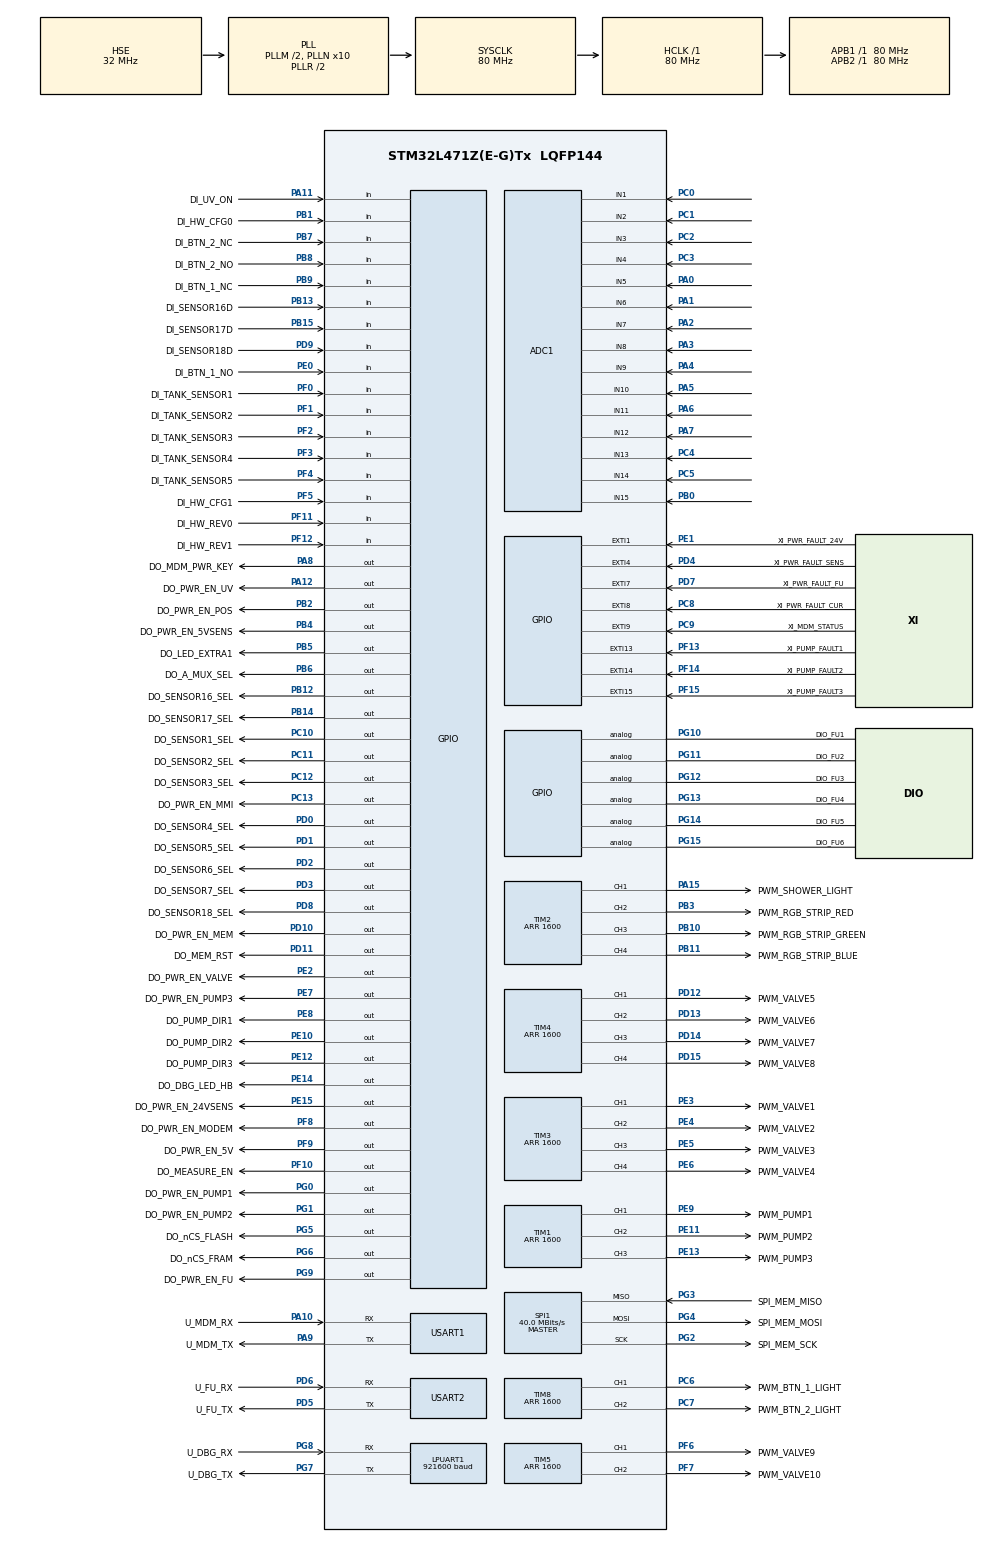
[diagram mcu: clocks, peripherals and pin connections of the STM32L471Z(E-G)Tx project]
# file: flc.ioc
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ADC1.Channel-0\#ChannelRegularConversion=ADC_CHANNEL_1
ADC1.Channel-1\#ChannelRegularConversion=ADC_CHANNEL_2
ADC1.Channel-10\#ChannelRegularConversion=ADC_CHANNEL_11
ADC1.Channel-11\#ChannelRegularConversion=ADC_CHANNEL_12
ADC1.Channel-12\#ChannelRegularConversion=ADC_CHANNEL_13
ADC1.Channel-13\#ChannelRegularConversion=ADC_CHANNEL_14
ADC1.Channel-14\#ChannelRegularConversion=ADC_CHANNEL_15
ADC1.Channel-2\#ChannelRegularConversion=ADC_CHANNEL_3
ADC1.Channel-3\#ChannelRegularConversion=ADC_CHANNEL_4
ADC1.Channel-4\#ChannelRegularConversion=ADC_CHANNEL_5
ADC1.Channel-5\#ChannelRegularConversion=ADC_CHANNEL_6
ADC1.Channel-6\#ChannelRegularConversion=ADC_CHANNEL_7
ADC1.Channel-7\#ChannelRegularConversion=ADC_CHANNEL_8
ADC1.Channel-8\#ChannelRegularConversion=ADC_CHANNEL_9
ADC1.Channel-9\#ChannelRegularConversion=ADC_CHANNEL_10
ADC1.ClockPrescaler=ADC_CLOCK_ASYNC_DIV12
ADC1.DMAContinuousRequests=ENABLE
ADC1.NbrOfConversion=15
ADC1.NbrOfConversionFlag=1
ADC1.OffsetNumber-0\#ChannelRegularConversion=ADC_OFFSET_NONE
ADC1.OffsetNumber-1\#ChannelRegularConversion=ADC_OFFSET_NONE
ADC1.OffsetNumber-10\#ChannelRegularConversion=ADC_OFFSET_NONE
ADC1.OffsetNumber-11\#ChannelRegularConversion=ADC_OFFSET_NONE
ADC1.OffsetNumber-12\#ChannelRegularConversion=ADC_OFFSET_NONE
ADC1.OffsetNumber-13\#ChannelRegularConversion=ADC_OFFSET_NONE
ADC1.OffsetNumber-14\#ChannelRegularConversion=ADC_OFFSET_NONE
ADC1.OffsetNumber-2\#ChannelRegularConversion=ADC_OFFSET_NONE
ADC1.OffsetNumber-3\#ChannelRegularConversion=ADC_OFFSET_NONE
ADC1.OffsetNumber-4\#ChannelRegularConversion=ADC_OFFSET_NONE
ADC1.OffsetNumber-5\#ChannelRegularConversion=ADC_OFFSET_NONE
ADC1.OffsetNumber-6\#ChannelRegularConversion=ADC_OFFSET_NONE
ADC1.OffsetNumber-7\#ChannelRegularConversion=ADC_OFFSET_NONE
ADC1.OffsetNumber-8\#ChannelRegularConversion=ADC_OFFSET_NONE
ADC1.OffsetNumber-9\#ChannelRegularConversion=ADC_OFFSET_NONE
ADC1.Overrun=ADC_OVR_DATA_OVERWRITTEN
ADC1.Rank-0\#ChannelRegularConversion=1
ADC1.Rank-1\#ChannelRegularConversion=2
ADC1.Rank-10\#ChannelRegularConversion=11
ADC1.Rank-11\#ChannelRegularConversion=12
ADC1.Rank-12\#ChannelRegularConversion=13
ADC1.Rank-13\#ChannelRegularConversion=14
ADC1.Rank-14\#ChannelRegularConversion=15
ADC1.Rank-2\#ChannelRegularConversion=3
ADC1.Rank-3\#ChannelRegularConversion=4
ADC1.Rank-4\#ChannelRegularConversion=5
ADC1.Rank-5\#ChannelRegularConversion=6
ADC1.Rank-6\#ChannelRegularConversion=7
ADC1.Rank-7\#ChannelRegularConversion=8
ADC1.Rank-8\#ChannelRegularConversion=9
ADC1.Rank-9\#ChannelRegularConversion=10
ADC1.SamplingTime-0\#ChannelRegularConversion=ADC_SAMPLETIME_2CYCLES_5
ADC1.SamplingTime-1\#ChannelRegularConversion=ADC_SAMPLETIME_2CYCLES_5
ADC1.SamplingTime-10\#ChannelRegularConversion=ADC_SAMPLETIME_2CYCLES_5
ADC1.SamplingTime-11\#ChannelRegularConversion=ADC_SAMPLETIME_2CYCLES_5
ADC1.SamplingTime-12\#ChannelRegularConversion=ADC_SAMPLETIME_2CYCLES_5
ADC1.SamplingTime-13\#ChannelRegularConversion=ADC_SAMPLETIME_2CYCLES_5
ADC1.SamplingTime-14\#ChannelRegularConversion=ADC_SAMPLETIME_2CYCLES_5
ADC1.SamplingTime-2\#ChannelRegularConversion=ADC_SAMPLETIME_2CYCLES_5
ADC1.SamplingTime-3\#ChannelRegularConversion=ADC_SAMPLETIME_2CYCLES_5
ADC1.SamplingTime-4\#ChannelRegularConversion=ADC_SAMPLETIME_2CYCLES_5
ADC1.SamplingTime-5\#ChannelRegularConversion=ADC_SAMPLETIME_2CYCLES_5
ADC1.SamplingTime-6\#ChannelRegularConversion=ADC_SAMPLETIME_2CYCLES_5
ADC1.SamplingTime-7\#ChannelRegularConversion=ADC_SAMPLETIME_2CYCLES_5
ADC1.SamplingTime-8\#ChannelRegularConversion=ADC_SAMPLETIME_2CYCLES_5
ADC1.SamplingTime-9\#ChannelRegularConversion=ADC_SAMPLETIME_2CYCLES_5
ADC1.master=1
Dma.ADC1.0.Direction=DMA_PERIPH_TO_MEMORY
Dma.ADC1.0.Instance=DMA1_Channel1
Dma.ADC1.0.MemDataAlignment=DMA_MDATAALIGN_WORD
Dma.ADC1.0.MemInc=DMA_MINC_ENABLE
Dma.ADC1.0.Mode=DMA_CIRCULAR
Dma.ADC1.0.PeriphDataAlignment=DMA_PDATAALIGN_HALFWORD
Dma.ADC1.0.PeriphInc=DMA_PINC_DISABLE
Dma.ADC1.0.Priority=DMA_PRIORITY_LOW
Dma.Request0=ADC1
IWDG.Prescaler=IWDG_PRESCALER_16
LPUART1.BaudRate=921600
LPUART1.WordLength=UART_WORDLENGTH_8B
Mcu.Family=STM32L4
Mcu.Name=STM32L471Z(E-G)Tx
Mcu.Package=LQFP144
NVIC.DMA1_Channel1_IRQn=true\:0\:0\:false\:false\:true\:false\:true
NVIC.EXTI15_10_IRQn=true\:0\:0\:false\:false\:true\:true\:true
NVIC.EXTI1_IRQn=true\:0\:0\:false\:false\:true\:true\:true
NVIC.EXTI4_IRQn=true\:0\:0\:false\:false\:true\:true\:true
NVIC.EXTI9_5_IRQn=true\:0\:0\:false\:false\:true\:true\:true
NVIC.LPUART1_IRQn=true\:0\:0\:false\:false\:true\:true\:true
NVIC.PriorityGroup=NVIC_PRIORITYGROUP_4
NVIC.SPI1_IRQn=true\:0\:0\:false\:false\:true\:true\:true
NVIC.TIM1_TRG_COM_TIM17_IRQn=true\:0\:0\:false\:false\:true\:false\:true
NVIC.TIM1_UP_TIM16_IRQn=true\:0\:0\:false\:false\:true\:false\:true
NVIC.TimeBase=TIM1_UP_TIM16_IRQn
NVIC.TimeBaseIP=TIM16
NVIC.USART1_IRQn=true\:0\:0\:false\:false\:true\:true\:true
NVIC.USART2_IRQn=true\:0\:0\:false\:false\:true\:true\:true
PA0.Signal=ADCx_IN5
PA1.Signal=ADCx_IN6
PA10.GPIO_Label=U_MDM_RX
PA10.GPIO_PuPd=GPIO_PULLUP
PA10.Mode=Asynchronous
PA10.Signal=USART1_RX
PA11.GPIO_Label=DI_UV_ON
PA11.GPIO_PuPd=GPIO_PULLDOWN
PA11.Signal=GPIO_Input
PA12.GPIO_Label=DO_PWR_EN_UV
PA12.PinState=GPIO_PIN_RESET
PA12.Signal=GPIO_Output
PA13\ (JTMS-SWDIO).GPIO_Label=SWDIO
PA13\ (JTMS-SWDIO).Mode=Serial_Wire
PA13\ (JTMS-SWDIO).Signal=SYS_JTMS-SWDIO
PA14\ (JTCK-SWCLK).GPIO_Label=SWCLK
PA14\ (JTCK-SWCLK).Mode=Serial_Wire
PA14\ (JTCK-SWCLK).Signal=SYS_JTCK-SWCLK
PA15\ (JTDI).GPIO_Label=PWM_SHOWER_LIGHT
PA15\ (JTDI).Signal=S_TIM2_CH1
PA2.Signal=ADCx_IN7
PA3.Signal=ADCx_IN8
PA4.Signal=ADCx_IN9
PA5.Signal=ADCx_IN10
PA6.Signal=ADCx_IN11
PA7.Signal=ADCx_IN12
PA8.GPIO_Label=DO_MDM_PWR_KEY
PA8.Signal=GPIO_Output
PA9.GPIO_Label=U_MDM_TX
PA9.GPIO_PuPd=GPIO_PULLUP
PA9.Mode=Asynchronous
PA9.Signal=USART1_TX
PB0.Signal=ADCx_IN15
PB1.GPIO_Label=DI_HW_CFG0
PB1.Signal=GPIO_Input
PB10.GPIO_Label=PWM_RGB_STRIP_GREEN
PB10.Signal=S_TIM2_CH3
PB11.GPIO_Label=PWM_RGB_STRIP_BLUE
PB11.Signal=S_TIM2_CH4
PB12.GPIO_Label=DO_SENSOR16_SEL
PB12.Signal=GPIO_Output
PB13.GPIO_Label=DI_SENSOR16D
PB13.GPIO_PuPd=GPIO_PULLUP
PB13.Signal=GPIO_Input
PB14.GPIO_Label=DO_SENSOR17_SEL
PB14.Signal=GPIO_Output
PB15.GPIO_Label=DI_SENSOR17D
PB15.GPIO_PuPd=GPIO_PULLUP
PB15.Signal=GPIO_Input
PB2.GPIO_Label=DO_PWR_EN_POS
PB2.PinState=GPIO_PIN_SET
PB2.Signal=GPIO_Output
PB3\ (JTDO-TRACESWO).GPIO_Label=PWM_RGB_STRIP_RED
PB3\ (JTDO-TRACESWO).Signal=S_TIM2_CH2
PB4\ (NJTRST).GPIO_Label=DO_PWR_EN_5VSENS
PB4\ (NJTRST).PinState=GPIO_PIN_SET
PB4\ (NJTRST).Signal=GPIO_Output
PB5.GPIO_Label=DO_LED_EXTRA1
PB5.Signal=GPIO_Output
PB6.GPIO_Label=DO_A_MUX_SEL
PB6.Signal=GPIO_Output
PB7.GPIO_Label=DI_BTN_2_NC
PB7.GPIO_PuPd=GPIO_PULLDOWN
PB7.Signal=GPIO_Input
PB8.GPIO_Label=DI_BTN_2_NO
PB8.GPIO_PuPd=GPIO_PULLDOWN
PB8.Signal=GPIO_Input
PB9.GPIO_Label=DI_BTN_1_NC
PB9.GPIO_PuPd=GPIO_PULLDOWN
PB9.Signal=GPIO_Input
PC0.Signal=ADCx_IN1
PC1.Signal=ADCx_IN2
PC10.GPIO_Label=DO_SENSOR1_SEL
PC10.Signal=GPIO_Output
PC11.GPIO_Label=DO_SENSOR2_SEL
PC11.Signal=GPIO_Output
PC12.GPIO_Label=DO_SENSOR3_SEL
PC12.Signal=GPIO_Output
PC13.GPIO_Label=DO_PWR_EN_MMI
PC13.PinState=GPIO_PIN_RESET
PC13.Signal=GPIO_Output
PC14-OSC32_IN\ (PC14).Mode=LSE-External-Oscillator
PC14-OSC32_IN\ (PC14).Signal=RCC_OSC32_IN
PC15-OSC32_OUT\ (PC15).Mode=LSE-External-Oscillator
PC15-OSC32_OUT\ (PC15).Signal=RCC_OSC32_OUT
PC2.Signal=ADCx_IN3
PC3.Signal=ADCx_IN4
PC4.Signal=ADCx_IN13
PC5.Signal=ADCx_IN14
PC6.GPIO_Label=PWM_BTN_1_LIGHT
PC6.Signal=S_TIM8_CH1
PC7.GPIO_Label=PWM_BTN_2_LIGHT
PC7.Signal=S_TIM8_CH2
PC8.GPIO_Label=XI_PWR_FAULT_CUR
PC8.GPIO_ModeDefaultEXTI=GPIO_MODE_IT_FALLING
PC8.GPIO_PuPd=GPIO_PULLUP
PC8.Signal=GPXTI8
PC9.GPIO_Label=XI_MDM_STATUS
PC9.GPIO_ModeDefaultEXTI=GPIO_MODE_IT_RISING_FALLING
PC9.GPIO_PuPd=GPIO_PULLDOWN
PC9.Signal=GPXTI9
PD0.GPIO_Label=DO_SENSOR4_SEL
PD0.Signal=GPIO_Output
PD1.GPIO_Label=DO_SENSOR5_SEL
PD1.Signal=GPIO_Output
PD10.GPIO_Label=DO_PWR_EN_MEM
PD10.PinState=GPIO_PIN_RESET
PD10.Signal=GPIO_Output
PD11.GPIO_Label=DO_MEM_RST
PD11.PinState=GPIO_PIN_SET
PD11.Signal=GPIO_Output
PD12.GPIO_Label=PWM_VALVE5
PD12.GPIO_Speed=GPIO_SPEED_FREQ_VERY_HIGH
PD12.Signal=S_TIM4_CH1
PD13.GPIO_Label=PWM_VALVE6
PD13.GPIO_Speed=GPIO_SPEED_FREQ_VERY_HIGH
PD13.Signal=S_TIM4_CH2
PD14.GPIO_Label=PWM_VALVE7
PD14.GPIO_Speed=GPIO_SPEED_FREQ_VERY_HIGH
PD14.Signal=S_TIM4_CH3
PD15.GPIO_Label=PWM_VALVE8
PD15.GPIO_Speed=GPIO_SPEED_FREQ_VERY_HIGH
PD15.Signal=S_TIM4_CH4
PD2.GPIO_Label=DO_SENSOR6_SEL
PD2.Signal=GPIO_Output
PD3.GPIO_Label=DO_SENSOR7_SEL
PD3.Signal=GPIO_Output
PD4.GPIO_Label=XI_PWR_FAULT_SENS
PD4.GPIO_ModeDefaultEXTI=GPIO_MODE_IT_FALLING
PD4.GPIO_PuPd=GPIO_PULLUP
PD4.Signal=GPXTI4
PD5.GPIO_Label=U_FU_TX
PD5.GPIO_PuPd=GPIO_PULLUP
PD5.Mode=Asynchronous
PD5.Signal=USART2_TX
PD6.GPIO_Label=U_FU_RX
PD6.GPIO_PuPd=GPIO_PULLUP
PD6.Mode=Asynchronous
PD6.Signal=USART2_RX
PD7.GPIO_Label=XI_PWR_FAULT_FU
PD7.GPIO_ModeDefaultEXTI=GPIO_MODE_IT_FALLING
PD7.GPIO_PuPd=GPIO_PULLUP
PD7.Signal=GPXTI7
PD8.GPIO_Label=DO_SENSOR18_SEL
PD8.Signal=GPIO_Output
PD9.GPIO_Label=DI_SENSOR18D
PD9.GPIO_PuPd=GPIO_PULLUP
PD9.Signal=GPIO_Input
PE0.GPIO_Label=DI_BTN_1_NO
PE0.GPIO_PuPd=GPIO_PULLDOWN
PE0.Signal=GPIO_Input
PE1.GPIO_Label=XI_PWR_FAULT_24V
PE1.GPIO_ModeDefaultEXTI=GPIO_MODE_IT_FALLING
PE1.GPIO_PuPd=GPIO_PULLUP
PE1.Signal=GPXTI1
PE10.GPIO_Label=DO_PUMP_DIR2
PE10.Signal=GPIO_Output
PE11.GPIO_Label=PWM_PUMP2
PE11.GPIO_PuPd=GPIO_PULLDOWN
PE11.Signal=S_TIM1_CH2
PE12.GPIO_Label=DO_PUMP_DIR3
PE12.Signal=GPIO_Output
PE13.GPIO_Label=PWM_PUMP3
PE13.GPIO_PuPd=GPIO_PULLDOWN
PE13.Signal=S_TIM1_CH3
PE14.GPIO_Label=DO_DBG_LED_HB
PE14.Signal=GPIO_Output
PE15.GPIO_Label=DO_PWR_EN_24VSENS
PE15.PinState=GPIO_PIN_SET
PE15.Signal=GPIO_Output
PE2.GPIO_Label=DO_PWR_EN_VALVE
PE2.PinState=GPIO_PIN_RESET
PE2.Signal=GPIO_Output
PE3.GPIO_Label=PWM_VALVE1
PE3.GPIO_Speed=GPIO_SPEED_FREQ_VERY_HIGH
PE3.Signal=S_TIM3_CH1
PE4.GPIO_Label=PWM_VALVE2
PE4.GPIO_Speed=GPIO_SPEED_FREQ_VERY_HIGH
PE4.Signal=S_TIM3_CH2
PE5.GPIO_Label=PWM_VALVE3
PE5.GPIO_Speed=GPIO_SPEED_FREQ_VERY_HIGH
PE5.Signal=S_TIM3_CH3
PE6.GPIO_Label=PWM_VALVE4
PE6.GPIO_Speed=GPIO_SPEED_FREQ_VERY_HIGH
PE6.Signal=S_TIM3_CH4
PE7.GPIO_Label=DO_PWR_EN_PUMP3
PE7.PinState=GPIO_PIN_RESET
PE7.Signal=GPIO_Output
PE8.GPIO_Label=DO_PUMP_DIR1
PE8.Signal=GPIO_Output
PE9.GPIO_Label=PWM_PUMP1
PE9.GPIO_PuPd=GPIO_PULLDOWN
PE9.Signal=S_TIM1_CH1
PF0.GPIO_Label=DI_TANK_SENSOR1
PF0.GPIO_PuPd=GPIO_PULLUP
PF0.Signal=GPIO_Input
PF1.GPIO_Label=DI_TANK_SENSOR2
PF1.GPIO_PuPd=GPIO_PULLUP
PF1.Signal=GPIO_Input
PF10.GPIO_Label=DO_MEASURE_EN
PF10.PinState=GPIO_PIN_SET
PF10.Signal=GPIO_Output
PF11.GPIO_Label=DI_HW_REV0
PF11.Signal=GPIO_Input
PF12.GPIO_Label=DI_HW_REV1
PF12.Signal=GPIO_Input
PF13.GPIO_Label=XI_PUMP_FAULT1
PF13.GPIO_ModeDefaultEXTI=GPIO_MODE_IT_FALLING
PF13.GPIO_PuPd=GPIO_PULLUP
PF13.Signal=GPXTI13
PF14.GPIO_Label=XI_PUMP_FAULT2
PF14.GPIO_ModeDefaultEXTI=GPIO_MODE_IT_FALLING
PF14.GPIO_PuPd=GPIO_PULLUP
PF14.Signal=GPXTI14
PF15.GPIO_Label=XI_PUMP_FAULT3
PF15.GPIO_ModeDefaultEXTI=GPIO_MODE_IT_FALLING
PF15.GPIO_PuPd=GPIO_PULLUP
PF15.Signal=GPXTI15
PF2.GPIO_Label=DI_TANK_SENSOR3
PF2.GPIO_PuPd=GPIO_PULLUP
PF2.Signal=GPIO_Input
PF3.GPIO_Label=DI_TANK_SENSOR4
PF3.GPIO_PuPd=GPIO_PULLUP
PF3.Signal=GPIO_Input
PF4.GPIO_Label=DI_TANK_SENSOR5
PF4.GPIO_PuPd=GPIO_PULLUP
PF4.Signal=GPIO_Input
PF5.GPIO_Label=DI_HW_CFG1
PF5.Signal=GPIO_Input
PF6.GPIO_Label=PWM_VALVE9
PF6.GPIO_Speed=GPIO_SPEED_FREQ_VERY_HIGH
PF6.Signal=S_TIM5_CH1
PF7.GPIO_Label=PWM_VALVE10
PF7.GPIO_Speed=GPIO_SPEED_FREQ_VERY_HIGH
PF7.Signal=S_TIM5_CH2
PF8.GPIO_Label=DO_PWR_EN_MODEM
PF8.PinState=GPIO_PIN_SET
PF8.Signal=GPIO_Output
PF9.GPIO_Label=DO_PWR_EN_5V
PF9.PinState=GPIO_PIN_SET
PF9.Signal=GPIO_Output
PG0.GPIO_Label=DO_PWR_EN_PUMP1
PG0.PinState=GPIO_PIN_RESET
PG0.Signal=GPIO_Output
PG1.GPIO_Label=DO_PWR_EN_PUMP2
PG1.PinState=GPIO_PIN_RESET
PG1.Signal=GPIO_Output
PG10.GPIO_Label=DIO_FU1
PG10.Signal=GPIO_Analog
PG11.GPIO_Label=DIO_FU2
PG11.Signal=GPIO_Analog
PG12.GPIO_Label=DIO_FU3
PG12.Signal=GPIO_Analog
PG13.GPIO_Label=DIO_FU4
PG13.Signal=GPIO_Analog
PG14.GPIO_Label=DIO_FU5
PG14.Signal=GPIO_Analog
PG15.GPIO_Label=DIO_FU6
PG15.Signal=GPIO_Analog
PG2.GPIO_Label=SPI_MEM_SCK
PG2.Mode=Full_Duplex_Master
PG2.Signal=SPI1_SCK
PG3.GPIO_Label=SPI_MEM_MISO
PG3.Mode=Full_Duplex_Master
PG3.Signal=SPI1_MISO
PG4.GPIO_Label=SPI_MEM_MOSI
PG4.Mode=Full_Duplex_Master
PG4.Signal=SPI1_MOSI
PG5.GPIO_Label=DO_nCS_FLASH
PG5.PinState=GPIO_PIN_SET
PG5.Signal=GPIO_Output
PG6.GPIO_Label=DO_nCS_FRAM
PG6.PinState=GPIO_PIN_SET
PG6.Signal=GPIO_Output
PG7.GPIO_Label=U_DBG_TX
PG7.Mode=Asynchronous
PG7.Signal=LPUART1_TX
PG8.GPIO_Label=U_DBG_RX
PG8.GPIO_PuPd=GPIO_PULLUP
PG8.Mode=Asynchronous
PG8.Signal=LPUART1_RX
PG9.GPIO_Label=DO_PWR_EN_FU
PG9.PinState=GPIO_PIN_RESET
PG9.Signal=GPIO_Output
PH0-OSC_IN\ (PH0).Mode=HSE-External-Oscillator
PH0-OSC_IN\ (PH0).Signal=RCC_OSC_IN
PH1-OSC_OUT\ (PH1).Mode=HSE-External-Oscillator
PH1-OSC_OUT\ (PH1).Signal=RCC_OSC_OUT
ProjectManager.HeapSize=0x00
ProjectManager.StackSize=0x1000
ProjectManager.TargetToolchain=MDK-ARM V5.27
RCC.ADCFreq_Value=64000000
RCC.AHBFreq_Value=80000000
RCC.APB1Freq_Value=80000000
RCC.APB1TimFreq_Value=80000000
RCC.APB2Freq_Value=80000000
RCC.APB2TimFreq_Value=80000000
RCC.CortexFreq_Value=80000000
RCC.HCLKFreq_Value=80000000
RCC.HSE_VALUE=32000000
RCC.HSI_VALUE=16000000
RCC.MSI_VALUE=4000000
RCC.PLLM=2
RCC.PLLN=10
RCC.PLLSourceVirtual=RCC_PLLSOURCE_HSE
RCC.RTCClockSelection=RCC_RTCCLKSOURCE_LSE
RCC.SYSCLKFreq_VALUE=80000000
RCC.SYSCLKSource=RCC_SYSCLKSOURCE_PLLCLK
RCC.VCOOutputFreq_Value=160000000
SH.ADCx_IN1.0=ADC1_IN1,IN1-Single-Ended
SH.ADCx_IN10.0=ADC1_IN10,IN10-Single-Ended
SH.ADCx_IN11.0=ADC1_IN11,IN11-Single-Ended
SH.ADCx_IN12.0=ADC1_IN12,IN12-Single-Ended
SH.ADCx_IN13.0=ADC1_IN13,IN13-Single-Ended
SH.ADCx_IN14.0=ADC1_IN14,IN14-Single-Ended
SH.ADCx_IN15.0=ADC1_IN15,IN15-Single-Ended
SH.ADCx_IN2.0=ADC1_IN2,IN2-Single-Ended
SH.ADCx_IN3.0=ADC1_IN3,IN3-Single-Ended
SH.ADCx_IN4.0=ADC1_IN4,IN4-Single-Ended
SH.ADCx_IN5.0=ADC1_IN5,IN5-Single-Ended
SH.ADCx_IN6.0=ADC1_IN6,IN6-Single-Ended
SH.ADCx_IN7.0=ADC1_IN7,IN7-Single-Ended
SH.ADCx_IN8.0=ADC1_IN8,IN8-Single-Ended
SH.ADCx_IN9.0=ADC1_IN9,IN9-Single-Ended
SH.S_TIM1_CH1.0=TIM1_CH1,PWM Generation1 CH1
SH.S_TIM1_CH2.0=TIM1_CH2,PWM Generation2 CH2
SH.S_TIM1_CH3.0=TIM1_CH3,PWM Generation3 CH3
SH.S_TIM2_CH1.0=TIM2_CH1,PWM Generation1 CH1
SH.S_TIM2_CH2.0=TIM2_CH2,PWM Generation2 CH2
SH.S_TIM2_CH3.0=TIM2_CH3,PWM Generation3 CH3
SH.S_TIM2_CH4.0=TIM2_CH4,PWM Generation4 CH4
SH.S_TIM3_CH1.0=TIM3_CH1,PWM Generation1 CH1
SH.S_TIM3_CH2.0=TIM3_CH2,PWM Generation2 CH2
SH.S_TIM3_CH3.0=TIM3_CH3,PWM Generation3 CH3
SH.S_TIM3_CH4.0=TIM3_CH4,PWM Generation4 CH4
SH.S_TIM4_CH1.0=TIM4_CH1,PWM Generation1 CH1
SH.S_TIM4_CH2.0=TIM4_CH2,PWM Generation2 CH2
SH.S_TIM4_CH3.0=TIM4_CH3,PWM Generation3 CH3
SH.S_TIM4_CH4.0=TIM4_CH4,PWM Generation4 CH4
SH.S_TIM5_CH1.0=TIM5_CH1,PWM Generation1 CH1
SH.S_TIM5_CH2.0=TIM5_CH2,PWM Generation2 CH2
SH.S_TIM8_CH1.0=TIM8_CH1,PWM Generation1 CH1
SH.S_TIM8_CH2.0=TIM8_CH2,PWM Generation2 CH2
SPI1.BaudRatePrescaler=SPI_BAUDRATEPRESCALER_2
SPI1.CalculateBaudRate=40.0 MBits/s
SPI1.DataSize=SPI_DATASIZE_8BIT
SPI1.Direction=SPI_DIRECTION_2LINES
SPI1.Mode=SPI_MODE_MASTER
SPI1.VirtualType=VM_MASTER
TIM1.AutoReloadPreload=TIM_AUTORELOAD_PRELOAD_ENABLE
TIM1.AutomaticOutput=TIM_AUTOMATICOUTPUT_ENABLE
TIM1.Channel-PWM\ Generation1\ CH1=TIM_CHANNEL_1
TIM1.Channel-PWM\ Generation2\ CH2=TIM_CHANNEL_2
TIM1.Channel-PWM\ Generation3\ CH3=TIM_CHANNEL_3
TIM1.Period=1600
TIM2.AutoReloadPreload=TIM_AUTORELOAD_PRELOAD_ENABLE
TIM2.Channel-PWM\ Generation1\ CH1=TIM_CHANNEL_1
TIM2.Channel-PWM\ Generation2\ CH2=TIM_CHANNEL_2
TIM2.Channel-PWM\ Generation3\ CH3=TIM_CHANNEL_3
TIM2.Channel-PWM\ Generation4\ CH4=TIM_CHANNEL_4
TIM2.Period=1600
TIM3.AutoReloadPreload=TIM_AUTORELOAD_PRELOAD_ENABLE
TIM3.Channel-PWM\ Generation1\ CH1=TIM_CHANNEL_1
TIM3.Channel-PWM\ Generation2\ CH2=TIM_CHANNEL_2
TIM3.Channel-PWM\ Generation3\ CH3=TIM_CHANNEL_3
TIM3.Channel-PWM\ Generation4\ CH4=TIM_CHANNEL_4
TIM3.Period=1600
TIM4.AutoReloadPreload=TIM_AUTORELOAD_PRELOAD_ENABLE
TIM4.Channel-PWM\ Generation1\ CH1=TIM_CHANNEL_1
TIM4.Channel-PWM\ Generation2\ CH2=TIM_CHANNEL_2
TIM4.Channel-PWM\ Generation3\ CH3=TIM_CHANNEL_3
TIM4.Channel-PWM\ Generation4\ CH4=TIM_CHANNEL_4
TIM4.Period=1600
TIM5.AutoReloadPreload=TIM_AUTORELOAD_PRELOAD_ENABLE
TIM5.Channel-PWM\ Generation1\ CH1=TIM_CHANNEL_1
TIM5.Channel-PWM\ Generation2\ CH2=TIM_CHANNEL_2
TIM5.Period=1600
TIM8.AutoReloadPreload=TIM_AUTORELOAD_PRELOAD_ENABLE
TIM8.AutomaticOutput=TIM_AUTOMATICOUTPUT_ENABLE
TIM8.Channel-PWM\ Generation1\ CH1=TIM_CHANNEL_1
TIM8.Channel-PWM\ Generation2\ CH2=TIM_CHANNEL_2
TIM8.Period=1600
USART1.VirtualMode-Asynchronous=VM_ASYNC
USART2.VirtualMode-Asynchronous=VM_ASYNC
VP_ADC1_Vref_Input.Mode=IN-Vrefint
VP_IWDG_VS_IWDG.Mode=IWDG_Activate
VP_RTC_VS_RTC_Activate.Mode=RTC_Enabled
VP_SYS_VS_tim16.Mode=TIM16
VP_TIM1_VS_ClockSourceINT.Mode=Internal
VP_TIM2_VS_ClockSourceINT.Mode=Internal
VP_TIM3_VS_ClockSourceINT.Mode=Internal
VP_TIM4_VS_ClockSourceINT.Mode=Internal
VP_TIM5_VS_ClockSourceINT.Mode=Internal
VP_TIM8_VS_ClockSourceINT.Mode=Internal
board=custom

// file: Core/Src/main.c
/* USER CODE BEGIN Header */
/**
  ******************************************************************************
  * @file           : main.c
  * @brief          : Main program body
  ******************************************************************************
  * @attention
  *
  * <h2><center>&copy; Copyright (c) 2021 STMicroelectronics.
  * All rights reserved.</center></h2>
  *
  * This software component is licensed by ST under BSD 3-Clause license,
  * the "License"; You may not use this file except in compliance with the
  * License. You may obtain a copy of the License at:
  *                        opensource.org/licenses/BSD-3-Clause
  *
  ******************************************************************************
  */
/* USER CODE END Header */
#include "main.h"

/* USER CODE BEGIN Includes */
#include "hal/hal.h"
#include "hal/wdt/wdt.h"
#include "plf/plf.h"
#include "plf/blc/blc.h"
#include "sif/sif.h"
#include "pow/pow.h"
#include "cif/cif.h"
#include "app/app.h"
/* USER CODE END Includes */

ADC_HandleTypeDef hadc1;
DMA_HandleTypeDef hdma_adc1;

IWDG_HandleTypeDef hiwdg;

UART_HandleTypeDef hlpuart1;
UART_HandleTypeDef huart1;
UART_HandleTypeDef huart2;

RTC_HandleTypeDef hrtc;

SPI_HandleTypeDef hspi1;

void SystemClock_Config(void);
static void MX_GPIO_Init(void);
static void MX_DMA_Init(void);
static void MX_LPUART1_UART_Init(void);
static void MX_SPI1_Init(void);
static void MX_ADC1_Init(void);
static void MX_TIM1_Init(void);
static void MX_TIM2_Init(void);
static void MX_TIM3_Init(void);
static void MX_TIM4_Init(void);
static void MX_USART1_UART_Init(void);
static void MX_USART2_UART_Init(void);
static void MX_TIM5_Init(void);
static void MX_TIM8_Init(void);
static void MX_RTC_Init(void);

int main(void)
{
  /* USER CODE BEGIN 1 */
  SCB->VTOR = APP_PROGRAM_FLASH_START;
  HalWdtFeed();
  /* USER CODE END 1 */

  /* MCU Configuration--------------------------------------------------------*/

  /* Reset of all peripherals, Initializes the Flash interface and the Systick. */
  HAL_Init();

  /* Configure the system clock */
  SystemClock_Config();

  /* Initialize all configured peripherals */
  MX_GPIO_Init();
  MX_DMA_Init();
  MX_LPUART1_UART_Init();
  MX_SPI1_Init();
  MX_ADC1_Init();
  MX_TIM1_Init();
  MX_TIM2_Init();
  MX_TIM3_Init();
  MX_TIM4_Init();
  MX_USART1_UART_Init();
  MX_USART2_UART_Init();
  MX_TIM5_Init();
  MX_TIM8_Init();
  MX_RTC_Init();
  /* USER CODE BEGIN 2 */
  HalWdtFeed();
  HalInterruptEnable(NULL);
  EvosInit();

	SIF_Init(true);
  HalInit();
	PlfInit();
	SIF_Init(false);

  // Application init handles SUP_Init and SHC_Init
  POW_Init();
  APP_Init();
  CIF_Init();  // Last called befor Evos Start
  /* USER CODE END 2 */

  /* Infinite loop */
  /* USER CODE BEGIN WHILE */
  EvosSchedulerStart(NULL);
    /* USER CODE END WHILE */

}

void SystemClock_Config(void)
{
  RCC_OscInitTypeDef RCC_OscInitStruct = {0};
  RCC_ClkInitTypeDef RCC_ClkInitStruct = {0};

  /** Configure the main internal regulator output voltage
  */
  if (HAL_PWREx_ControlVoltageScaling(PWR_REGULATOR_VOLTAGE_SCALE1) != HAL_OK)
  {
    Error_Handler();
  }
  /** Configure LSE Drive Capability
  */
  HAL_PWR_EnableBkUpAccess();
  __HAL_RCC_LSEDRIVE_CONFIG(RCC_LSEDRIVE_LOW);
  /** Initializes the RCC Oscillators according to the specified parameters
  * in the RCC_OscInitTypeDef structure.
  */
  RCC_OscInitStruct.OscillatorType = RCC_OSCILLATORTYPE_LSI|RCC_OSCILLATORTYPE_HSE
                              |RCC_OSCILLATORTYPE_LSE;
  RCC_OscInitStruct.HSEState = RCC_HSE_ON;
  RCC_OscInitStruct.LSEState = RCC_LSE_ON;
  RCC_OscInitStruct.LSIState = RCC_LSI_ON;
  RCC_OscInitStruct.PLL.PLLState = RCC_PLL_ON;
  RCC_OscInitStruct.PLL.PLLSource = RCC_PLLSOURCE_HSE;
  RCC_OscInitStruct.PLL.PLLM = 2;
  RCC_OscInitStruct.PLL.PLLN = 10;
  RCC_OscInitStruct.PLL.PLLP = RCC_PLLP_DIV7;
  RCC_OscInitStruct.PLL.PLLQ = RCC_PLLQ_DIV2;
  RCC_OscInitStruct.PLL.PLLR = RCC_PLLR_DIV2;
  if (HAL_RCC_OscConfig(&RCC_OscInitStruct) != HAL_OK)
  {
    Error_Handler();
  }
  /** Initializes the CPU, AHB and APB buses clocks
  */
  RCC_ClkInitStruct.ClockType = RCC_CLOCKTYPE_HCLK|RCC_CLOCKTYPE_SYSCLK
                              |RCC_CLOCKTYPE_PCLK1|RCC_CLOCKTYPE_PCLK2;
  RCC_ClkInitStruct.SYSCLKSource = RCC_SYSCLKSOURCE_PLLCLK;
  RCC_ClkInitStruct.AHBCLKDivider = RCC_SYSCLK_DIV1;
  RCC_ClkInitStruct.APB1CLKDivider = RCC_HCLK_DIV1;
  RCC_ClkInitStruct.APB2CLKDivider = RCC_HCLK_DIV1;

  if (HAL_RCC_ClockConfig(&RCC_ClkInitStruct, FLASH_LATENCY_4) != HAL_OK)
  {
    Error_Handler();
  }
}

static void MX_ADC1_Init(void)
{

  ADC_MultiModeTypeDef multimode = {0};
  ADC_ChannelConfTypeDef sConfig = {0};

  /** Common config
  */
  hadc1.Instance = ADC1;
  hadc1.Init.ClockPrescaler = ADC_CLOCK_ASYNC_DIV12;
  hadc1.Init.Resolution = ADC_RESOLUTION_12B;
  hadc1.Init.DataAlign = ADC_DATAALIGN_RIGHT;
  hadc1.Init.ScanConvMode = ADC_SCAN_ENABLE;
  hadc1.Init.EOCSelection = ADC_EOC_SINGLE_CONV;
  hadc1.Init.LowPowerAutoWait = DISABLE;
  hadc1.Init.ContinuousConvMode = DISABLE;
  hadc1.Init.NbrOfConversion = 15;
  hadc1.Init.DiscontinuousConvMode = DISABLE;
  hadc1.Init.ExternalTrigConv = ADC_SOFTWARE_START;
  hadc1.Init.ExternalTrigConvEdge = ADC_EXTERNALTRIGCONVEDGE_NONE;
  hadc1.Init.DMAContinuousRequests = ENABLE;
  hadc1.Init.Overrun = ADC_OVR_DATA_OVERWRITTEN;
  hadc1.Init.OversamplingMode = DISABLE;
  if (HAL_ADC_Init(&hadc1) != HAL_OK)
  {
    Error_Handler();
  }
  /** Configure the ADC multi-mode
  */
  multimode.Mode = ADC_MODE_INDEPENDENT;
  if (HAL_ADCEx_MultiModeConfigChannel(&hadc1, &multimode) != HAL_OK)
  {
    Error_Handler();
  }
  /** Configure Regular Channel
  */
  sConfig.Channel = ADC_CHANNEL_1;
  sConfig.Rank = ADC_REGULAR_RANK_1;
  sConfig.SamplingTime = ADC_SAMPLETIME_2CYCLES_5;
  sConfig.SingleDiff = ADC_SINGLE_ENDED;
  sConfig.OffsetNumber = ADC_OFFSET_NONE;
  sConfig.Offset = 0;
  if (HAL_ADC_ConfigChannel(&hadc1, &sConfig) != HAL_OK)
  {
    Error_Handler();
  }
  /** Configure Regular Channel
  */
  sConfig.Channel = ADC_CHANNEL_2;
  sConfig.Rank = ADC_REGULAR_RANK_2;
  if (HAL_ADC_ConfigChannel(&hadc1, &sConfig) != HAL_OK)
  {
    Error_Handler();
  }
  /** Configure Regular Channel
  */
  sConfig.Channel = ADC_CHANNEL_3;
  sConfig.Rank = ADC_REGULAR_RANK_3;
  if (HAL_ADC_ConfigChannel(&hadc1, &sConfig) != HAL_OK)
  {
    Error_Handler();
  }
  /** Configure Regular Channel
  */
  sConfig.Channel = ADC_CHANNEL_4;
  sConfig.Rank = ADC_REGULAR_RANK_4;
  if (HAL_ADC_ConfigChannel(&hadc1, &sConfig) != HAL_OK)
  {
    Error_Handler();
  }
  /** Configure Regular Channel
  */
  sConfig.Channel = ADC_CHANNEL_5;
  sConfig.Rank = ADC_REGULAR_RANK_5;
  if (HAL_ADC_ConfigChannel(&hadc1, &sConfig) != HAL_OK)
  {
    Error_Handler();
  }
  /** Configure Regular Channel
  */
  sConfig.Channel = ADC_CHANNEL_6;
  sConfig.Rank = ADC_REGULAR_RANK_6;
  if (HAL_ADC_ConfigChannel(&hadc1, &sConfig) != HAL_OK)
  {
    Error_Handler();
  }
  /** Configure Regular Channel
  */
  sConfig.Channel = ADC_CHANNEL_7;
  sConfig.Rank = ADC_REGULAR_RANK_7;
  if (HAL_ADC_ConfigChannel(&hadc1, &sConfig) != HAL_OK)
  {
    Error_Handler();
  }
  /** Configure Regular Channel
  */
  sConfig.Channel = ADC_CHANNEL_8;
  sConfig.Rank = ADC_REGULAR_RANK_8;
  if (HAL_ADC_ConfigChannel(&hadc1, &sConfig) != HAL_OK)
  {
    Error_Handler();
  }
  /** Configure Regular Channel
  */
  sConfig.Channel = ADC_CHANNEL_9;
  sConfig.Rank = ADC_REGULAR_RANK_9;
  if (HAL_ADC_ConfigChannel(&hadc1, &sConfig) != HAL_OK)
  {
    Error_Handler();
  }
  /** Configure Regular Channel
  */
  sConfig.Channel = ADC_CHANNEL_10;
  sConfig.Rank = ADC_REGULAR_RANK_10;
  if (HAL_ADC_ConfigChannel(&hadc1, &sConfig) != HAL_OK)
  {
    Error_Handler();
  }
  /** Configure Regular Channel
  */
  sConfig.Channel = ADC_CHANNEL_11;
  sConfig.Rank = ADC_REGULAR_RANK_11;
  if (HAL_ADC_ConfigChannel(&hadc1, &sConfig) != HAL_OK)
  {
    Error_Handler();
  }
  /** Configure Regular Channel
  */
  sConfig.Channel = ADC_CHANNEL_12;
  sConfig.Rank = ADC_REGULAR_RANK_12;
  if (HAL_ADC_ConfigChannel(&hadc1, &sConfig) != HAL_OK)
  {
    Error_Handler();
  }
  /** Configure Regular Channel
  */
  sConfig.Channel = ADC_CHANNEL_13;
  sConfig.Rank = ADC_REGULAR_RANK_13;
  if (HAL_ADC_ConfigChannel(&hadc1, &sConfig) != HAL_OK)
  {
    Error_Handler();
  }
  /** Configure Regular Channel
  */
  sConfig.Channel = ADC_CHANNEL_14;
  sConfig.Rank = ADC_REGULAR_RANK_14;
  if (HAL_ADC_ConfigChannel(&hadc1, &sConfig) != HAL_OK)
  {
    Error_Handler();
  }
  /** Configure Regular Channel
  */
  sConfig.Channel = ADC_CHANNEL_15;
  sConfig.Rank = ADC_REGULAR_RANK_15;
  if (HAL_ADC_ConfigChannel(&hadc1, &sConfig) != HAL_OK)
  {
    Error_Handler();
  }

}

void MX_IWDG_Init(void)
{

  hiwdg.Instance = IWDG;
  hiwdg.Init.Prescaler = IWDG_PRESCALER_16;
  hiwdg.Init.Window = 4095;
  hiwdg.Init.Reload = 4095;
  if (HAL_IWDG_Init(&hiwdg) != HAL_OK)
  {
    Error_Handler();
  }

}

static void MX_LPUART1_UART_Init(void)
{

  hlpuart1.Instance = LPUART1;
  hlpuart1.Init.BaudRate = 921600;
  hlpuart1.Init.WordLength = UART_WORDLENGTH_8B;
  hlpuart1.Init.StopBits = UART_STOPBITS_1;
  hlpuart1.Init.Parity = UART_PARITY_NONE;
  hlpuart1.Init.Mode = UART_MODE_TX_RX;
  hlpuart1.Init.HwFlowCtl = UART_HWCONTROL_NONE;
  hlpuart1.Init.OneBitSampling = UART_ONE_BIT_SAMPLE_DISABLE;
  hlpuart1.AdvancedInit.AdvFeatureInit = UART_ADVFEATURE_NO_INIT;
  if (HAL_UART_Init(&hlpuart1) != HAL_OK)
  {
    Error_Handler();
  }

}

static void MX_USART1_UART_Init(void)
{

  huart1.Instance = USART1;
  huart1.Init.BaudRate = 115200;
  huart1.Init.WordLength = UART_WORDLENGTH_8B;
  huart1.Init.StopBits = UART_STOPBITS_1;
  huart1.Init.Parity = UART_PARITY_NONE;
  huart1.Init.Mode = UART_MODE_TX_RX;
  huart1.Init.HwFlowCtl = UART_HWCONTROL_NONE;
  huart1.Init.OverSampling = UART_OVERSAMPLING_16;
  huart1.Init.OneBitSampling = UART_ONE_BIT_SAMPLE_DISABLE;
  huart1.AdvancedInit.AdvFeatureInit = UART_ADVFEATURE_NO_INIT;
  if (HAL_UART_Init(&huart1) != HAL_OK)
  {
    Error_Handler();
  }

}

static void MX_USART2_UART_Init(void)
{

  huart2.Instance = USART2;
  huart2.Init.BaudRate = 115200;
  huart2.Init.WordLength = UART_WORDLENGTH_8B;
  huart2.Init.StopBits = UART_STOPBITS_1;
  huart2.Init.Parity = UART_PARITY_NONE;
  huart2.Init.Mode = UART_MODE_TX_RX;
  huart2.Init.HwFlowCtl = UART_HWCONTROL_NONE;
  huart2.Init.OverSampling = UART_OVERSAMPLING_16;
  huart2.Init.OneBitSampling = UART_ONE_BIT_SAMPLE_DISABLE;
  huart2.AdvancedInit.AdvFeatureInit = UART_ADVFEATURE_NO_INIT;
  if (HAL_UART_Init(&huart2) != HAL_OK)
  {
    Error_Handler();
  }

}

static void MX_RTC_Init(void)
{

  /** Initialize RTC Only
  */
  hrtc.Instance = RTC;
  hrtc.Init.HourFormat = RTC_HOURFORMAT_24;
  hrtc.Init.AsynchPrediv = 127;
  hrtc.Init.SynchPrediv = 255;
  hrtc.Init.OutPut = RTC_OUTPUT_DISABLE;
  hrtc.Init.OutPutRemap = RTC_OUTPUT_REMAP_NONE;
  hrtc.Init.OutPutPolarity = RTC_OUTPUT_POLARITY_HIGH;
  hrtc.Init.OutPutType = RTC_OUTPUT_TYPE_OPENDRAIN;
  if (HAL_RTC_Init(&hrtc) != HAL_OK)
  {
    Error_Handler();
  }

}

static void MX_SPI1_Init(void)
{

  /* SPI1 parameter configuration*/
  hspi1.Instance = SPI1;
  hspi1.Init.Mode = SPI_MODE_MASTER;
  hspi1.Init.Direction = SPI_DIRECTION_2LINES;
  hspi1.Init.DataSize = SPI_DATASIZE_8BIT;
  hspi1.Init.CLKPolarity = SPI_POLARITY_LOW;
  hspi1.Init.CLKPhase = SPI_PHASE_1EDGE;
  hspi1.Init.NSS = SPI_NSS_SOFT;
  hspi1.Init.BaudRatePrescaler = SPI_BAUDRATEPRESCALER_2;
  hspi1.Init.FirstBit = SPI_FIRSTBIT_MSB;
  hspi1.Init.TIMode = SPI_TIMODE_DISABLE;
  hspi1.Init.CRCCalculation = SPI_CRCCALCULATION_DISABLE;
  hspi1.Init.CRCPolynomial = 7;
  hspi1.Init.CRCLength = SPI_CRC_LENGTH_DATASIZE;
  hspi1.Init.NSSPMode = SPI_NSS_PULSE_ENABLE;
  if (HAL_SPI_Init(&hspi1) != HAL_OK)
  {
    Error_Handler();
  }

}

static void MX_TIM1_Init(void)
{

  LL_TIM_InitTypeDef TIM_InitStruct = {0};
  LL_TIM_OC_InitTypeDef TIM_OC_InitStruct = {0};
  LL_TIM_BDTR_InitTypeDef TIM_BDTRInitStruct = {0};

  LL_GPIO_InitTypeDef GPIO_InitStruct = {0};

  /* Peripheral clock enable */
  LL_APB2_GRP1_EnableClock(LL_APB2_GRP1_PERIPH_TIM1);

  /* TIM1 interrupt Init */
  NVIC_SetPriority(TIM1_UP_TIM16_IRQn, NVIC_EncodePriority(NVIC_GetPriorityGrouping(),0, 0));
  NVIC_EnableIRQ(TIM1_UP_TIM16_IRQn);
  NVIC_SetPriority(TIM1_TRG_COM_TIM17_IRQn, NVIC_EncodePriority(NVIC_GetPriorityGrouping(),0, 0));
  NVIC_EnableIRQ(TIM1_TRG_COM_TIM17_IRQn);

  TIM_InitStruct.Prescaler = 0;
  TIM_InitStruct.CounterMode = LL_TIM_COUNTERMODE_UP;
  TIM_InitStruct.Autoreload = 1600;
  TIM_InitStruct.ClockDivision = LL_TIM_CLOCKDIVISION_DIV1;
  TIM_InitStruct.RepetitionCounter = 0;
  LL_TIM_Init(TIM1, &TIM_InitStruct);
  LL_TIM_EnableARRPreload(TIM1);
  LL_TIM_SetClockSource(TIM1, LL_TIM_CLOCKSOURCE_INTERNAL);
  LL_TIM_OC_EnablePreload(TIM1, LL_TIM_CHANNEL_CH1);
  TIM_OC_InitStruct.OCMode = LL_TIM_OCMODE_PWM1;
  TIM_OC_InitStruct.OCState = LL_TIM_OCSTATE_DISABLE;
  TIM_OC_InitStruct.OCNState = LL_TIM_OCSTATE_DISABLE;
  TIM_OC_InitStruct.CompareValue = 0;
  TIM_OC_InitStruct.OCPolarity = LL_TIM_OCPOLARITY_HIGH;
  TIM_OC_InitStruct.OCNPolarity = LL_TIM_OCPOLARITY_HIGH;
  TIM_OC_InitStruct.OCIdleState = LL_TIM_OCIDLESTATE_LOW;
  TIM_OC_InitStruct.OCNIdleState = LL_TIM_OCIDLESTATE_LOW;
  LL_TIM_OC_Init(TIM1, LL_TIM_CHANNEL_CH1, &TIM_OC_InitStruct);
  LL_TIM_OC_DisableFast(TIM1, LL_TIM_CHANNEL_CH1);
  LL_TIM_OC_EnablePreload(TIM1, LL_TIM_CHANNEL_CH2);
  LL_TIM_OC_Init(TIM1, LL_TIM_CHANNEL_CH2, &TIM_OC_InitStruct);
  LL_TIM_OC_DisableFast(TIM1, LL_TIM_CHANNEL_CH2);
  LL_TIM_OC_EnablePreload(TIM1, LL_TIM_CHANNEL_CH3);
  LL_TIM_OC_Init(TIM1, LL_TIM_CHANNEL_CH3, &TIM_OC_InitStruct);
  LL_TIM_OC_DisableFast(TIM1, LL_TIM_CHANNEL_CH3);
  LL_TIM_SetOCRefClearInputSource(TIM1, LL_TIM_OCREF_CLR_INT_NC);
  LL_TIM_DisableExternalClock(TIM1);
  LL_TIM_ConfigETR(TIM1, LL_TIM_ETR_POLARITY_NONINVERTED, LL_TIM_ETR_PRESCALER_DIV1, LL_TIM_ETR_FILTER_FDIV1);
  LL_TIM_SetTriggerOutput(TIM1, LL_TIM_TRGO_RESET);
  LL_TIM_SetTriggerOutput2(TIM1, LL_TIM_TRGO2_RESET);
  LL_TIM_DisableMasterSlaveMode(TIM1);
  TIM_BDTRInitStruct.OSSRState = LL_TIM_OSSR_DISABLE;
  TIM_BDTRInitStruct.OSSIState = LL_TIM_OSSI_DISABLE;
  TIM_BDTRInitStruct.LockLevel = LL_TIM_LOCKLEVEL_OFF;
  TIM_BDTRInitStruct.DeadTime = 0;
  TIM_BDTRInitStruct.BreakState = LL_TIM_BREAK_DISABLE;
  TIM_BDTRInitStruct.BreakPolarity = LL_TIM_BREAK_POLARITY_HIGH;
  TIM_BDTRInitStruct.BreakFilter = LL_TIM_BREAK_FILTER_FDIV1;
  TIM_BDTRInitStruct.Break2State = LL_TIM_BREAK2_DISABLE;
  TIM_BDTRInitStruct.Break2Polarity = LL_TIM_BREAK2_POLARITY_HIGH;
  TIM_BDTRInitStruct.Break2Filter = LL_TIM_BREAK2_FILTER_FDIV1;
  TIM_BDTRInitStruct.AutomaticOutput = LL_TIM_AUTOMATICOUTPUT_ENABLE;
  LL_TIM_BDTR_Init(TIM1, &TIM_BDTRInitStruct);
  /* USER CODE BEGIN TIM1_Init 2 */
  LL_TIM_EnableCounter(TIM1);
  /* USER CODE END TIM1_Init 2 */
  LL_AHB2_GRP1_EnableClock(LL_AHB2_GRP1_PERIPH_GPIOE);
  /**TIM1 GPIO Configuration
  PE9   ------> TIM1_CH1
  PE11   ------> TIM1_CH2
  PE13   ------> TIM1_CH3
  */
  GPIO_InitStruct.Pin = LL_GPIO_PIN_9|LL_GPIO_PIN_11|LL_GPIO_PIN_13;
  GPIO_InitStruct.Mode = LL_GPIO_MODE_ALTERNATE;
  GPIO_InitStruct.Speed = LL_GPIO_SPEED_FREQ_LOW;
  GPIO_InitStruct.OutputType = LL_GPIO_OUTPUT_PUSHPULL;
  GPIO_InitStruct.Pull = LL_GPIO_PULL_DOWN;
  GPIO_InitStruct.Alternate = LL_GPIO_AF_1;
  LL_GPIO_Init(GPIOE, &GPIO_InitStruct);

}

static void MX_TIM2_Init(void)
{

  LL_TIM_InitTypeDef TIM_InitStruct = {0};
  LL_TIM_OC_InitTypeDef TIM_OC_InitStruct = {0};

  LL_GPIO_InitTypeDef GPIO_InitStruct = {0};

  /* Peripheral clock enable */
  LL_APB1_GRP1_EnableClock(LL_APB1_GRP1_PERIPH_TIM2);

  TIM_InitStruct.Prescaler = 0;
  TIM_InitStruct.CounterMode = LL_TIM_COUNTERMODE_UP;
  TIM_InitStruct.Autoreload = 1600;
  TIM_InitStruct.ClockDivision = LL_TIM_CLOCKDIVISION_DIV1;
  LL_TIM_Init(TIM2, &TIM_InitStruct);
  LL_TIM_EnableARRPreload(TIM2);
  LL_TIM_SetClockSource(TIM2, LL_TIM_CLOCKSOURCE_INTERNAL);
  LL_TIM_OC_EnablePreload(TIM2, LL_TIM_CHANNEL_CH1);
  TIM_OC_InitStruct.OCMode = LL_TIM_OCMODE_PWM1;
  TIM_OC_InitStruct.OCState = LL_TIM_OCSTATE_DISABLE;
  TIM_OC_InitStruct.OCNState = LL_TIM_OCSTATE_DISABLE;
  TIM_OC_InitStruct.CompareValue = 0;
  TIM_OC_InitStruct.OCPolarity = LL_TIM_OCPOLARITY_HIGH;
  LL_TIM_OC_Init(TIM2, LL_TIM_CHANNEL_CH1, &TIM_OC_InitStruct);
  LL_TIM_OC_DisableFast(TIM2, LL_TIM_CHANNEL_CH1);
  LL_TIM_OC_EnablePreload(TIM2, LL_TIM_CHANNEL_CH2);
  LL_TIM_OC_Init(TIM2, LL_TIM_CHANNEL_CH2, &TIM_OC_InitStruct);
  LL_TIM_OC_DisableFast(TIM2, LL_TIM_CHANNEL_CH2);
  LL_TIM_OC_EnablePreload(TIM2, LL_TIM_CHANNEL_CH3);
  LL_TIM_OC_Init(TIM2, LL_TIM_CHANNEL_CH3, &TIM_OC_InitStruct);
  LL_TIM_OC_DisableFast(TIM2, LL_TIM_CHANNEL_CH3);
  LL_TIM_OC_EnablePreload(TIM2, LL_TIM_CHANNEL_CH4);
  LL_TIM_OC_Init(TIM2, LL_TIM_CHANNEL_CH4, &TIM_OC_InitStruct);
  LL_TIM_OC_DisableFast(TIM2, LL_TIM_CHANNEL_CH4);
  LL_TIM_SetOCRefClearInputSource(TIM2, LL_TIM_OCREF_CLR_INT_NC);
  LL_TIM_DisableExternalClock(TIM2);
  LL_TIM_ConfigETR(TIM2, LL_TIM_ETR_POLARITY_NONINVERTED, LL_TIM_ETR_PRESCALER_DIV1, LL_TIM_ETR_FILTER_FDIV1);
  LL_TIM_SetTriggerOutput(TIM2, LL_TIM_TRGO_RESET);
  LL_TIM_DisableMasterSlaveMode(TIM2);
  /* USER CODE BEGIN TIM2_Init 2 */
  LL_TIM_EnableCounter(TIM2);
  /* USER CODE END TIM2_Init 2 */
  LL_AHB2_GRP1_EnableClock(LL_AHB2_GRP1_PERIPH_GPIOB);
  LL_AHB2_GRP1_EnableClock(LL_AHB2_GRP1_PERIPH_GPIOA);
  /**TIM2 GPIO Configuration
  PB10   ------> TIM2_CH3
  PB11   ------> TIM2_CH4
  PA15 (JTDI)   ------> TIM2_CH1
  PB3 (JTDO-TRACESWO)   ------> TIM2_CH2
  */
  GPIO_InitStruct.Pin = LL_GPIO_PIN_10|LL_GPIO_PIN_11|LL_GPIO_PIN_3;
  GPIO_InitStruct.Mode = LL_GPIO_MODE_ALTERNATE;
  GPIO_InitStruct.Speed = LL_GPIO_SPEED_FREQ_LOW;
  GPIO_InitStruct.OutputType = LL_GPIO_OUTPUT_PUSHPULL;
  GPIO_InitStruct.Pull = LL_GPIO_PULL_NO;
  GPIO_InitStruct.Alternate = LL_GPIO_AF_1;
  LL_GPIO_Init(GPIOB, &GPIO_InitStruct);

  GPIO_InitStruct.Pin = LL_GPIO_PIN_15;
  GPIO_InitStruct.Mode = LL_GPIO_MODE_ALTERNATE;
  GPIO_InitStruct.Speed = LL_GPIO_SPEED_FREQ_LOW;
  GPIO_InitStruct.OutputType = LL_GPIO_OUTPUT_PUSHPULL;
  GPIO_InitStruct.Pull = LL_GPIO_PULL_NO;
  GPIO_InitStruct.Alternate = LL_GPIO_AF_1;
  LL_GPIO_Init(GPIOA, &GPIO_InitStruct);

}

static void MX_TIM3_Init(void)
{

  LL_TIM_InitTypeDef TIM_InitStruct = {0};
  LL_TIM_OC_InitTypeDef TIM_OC_InitStruct = {0};

  LL_GPIO_InitTypeDef GPIO_InitStruct = {0};

  /* Peripheral clock enable */
  LL_APB1_GRP1_EnableClock(LL_APB1_GRP1_PERIPH_TIM3);

  TIM_InitStruct.Prescaler = 0;
  TIM_InitStruct.CounterMode = LL_TIM_COUNTERMODE_UP;
  TIM_InitStruct.Autoreload = 1600;
  TIM_InitStruct.ClockDivision = LL_TIM_CLOCKDIVISION_DIV1;
  LL_TIM_Init(TIM3, &TIM_InitStruct);
  LL_TIM_EnableARRPreload(TIM3);
  LL_TIM_SetClockSource(TIM3, LL_TIM_CLOCKSOURCE_INTERNAL);
  LL_TIM_OC_EnablePreload(TIM3, LL_TIM_CHANNEL_CH1);
  TIM_OC_InitStruct.OCMode = LL_TIM_OCMODE_PWM1;
  TIM_OC_InitStruct.OCState = LL_TIM_OCSTATE_DISABLE;
  TIM_OC_InitStruct.OCNState = LL_TIM_OCSTATE_DISABLE;
  TIM_OC_InitStruct.CompareValue = 0;
  TIM_OC_InitStruct.OCPolarity = LL_TIM_OCPOLARITY_HIGH;
  LL_TIM_OC_Init(TIM3, LL_TIM_CHANNEL_CH1, &TIM_OC_InitStruct);
  LL_TIM_OC_DisableFast(TIM3, LL_TIM_CHANNEL_CH1);
  LL_TIM_OC_EnablePreload(TIM3, LL_TIM_CHANNEL_CH2);
  LL_TIM_OC_Init(TIM3, LL_TIM_CHANNEL_CH2, &TIM_OC_InitStruct);
  LL_TIM_OC_DisableFast(TIM3, LL_TIM_CHANNEL_CH2);
  LL_TIM_OC_EnablePreload(TIM3, LL_TIM_CHANNEL_CH3);
  LL_TIM_OC_Init(TIM3, LL_TIM_CHANNEL_CH3, &TIM_OC_InitStruct);
  LL_TIM_OC_DisableFast(TIM3, LL_TIM_CHANNEL_CH3);
  LL_TIM_OC_EnablePreload(TIM3, LL_TIM_CHANNEL_CH4);
  LL_TIM_OC_Init(TIM3, LL_TIM_CHANNEL_CH4, &TIM_OC_InitStruct);
  LL_TIM_OC_DisableFast(TIM3, LL_TIM_CHANNEL_CH4);
  LL_TIM_SetOCRefClearInputSource(TIM3, LL_TIM_OCREF_CLR_INT_NC);
  LL_TIM_DisableExternalClock(TIM3);
  LL_TIM_ConfigETR(TIM3, LL_TIM_ETR_POLARITY_NONINVERTED, LL_TIM_ETR_PRESCALER_DIV1, LL_TIM_ETR_FILTER_FDIV1);
  LL_TIM_SetTriggerOutput(TIM3, LL_TIM_TRGO_RESET);
  LL_TIM_DisableMasterSlaveMode(TIM3);
  /* USER CODE BEGIN TIM3_Init 2 */
  LL_TIM_EnableCounter(TIM3);
  /* USER CODE END TIM3_Init 2 */
  LL_AHB2_GRP1_EnableClock(LL_AHB2_GRP1_PERIPH_GPIOE);
  /**TIM3 GPIO Configuration
  PE3   ------> TIM3_CH1
  PE4   ------> TIM3_CH2
  PE5   ------> TIM3_CH3
  PE6   ------> TIM3_CH4
  */
  GPIO_InitStruct.Pin = LL_GPIO_PIN_3|LL_GPIO_PIN_4|LL_GPIO_PIN_5|LL_GPIO_PIN_6;
  GPIO_InitStruct.Mode = LL_GPIO_MODE_ALTERNATE;
  GPIO_InitStruct.Speed = LL_GPIO_SPEED_FREQ_VERY_HIGH;
  GPIO_InitStruct.OutputType = LL_GPIO_OUTPUT_PUSHPULL;
  GPIO_InitStruct.Pull = LL_GPIO_PULL_NO;
  GPIO_InitStruct.Alternate = LL_GPIO_AF_2;
  LL_GPIO_Init(GPIOE, &GPIO_InitStruct);

}

static void MX_TIM4_Init(void)
{

  LL_TIM_InitTypeDef TIM_InitStruct = {0};
  LL_TIM_OC_InitTypeDef TIM_OC_InitStruct = {0};

  LL_GPIO_InitTypeDef GPIO_InitStruct = {0};

  /* Peripheral clock enable */
  LL_APB1_GRP1_EnableClock(LL_APB1_GRP1_PERIPH_TIM4);

  TIM_InitStruct.Prescaler = 0;
  TIM_InitStruct.CounterMode = LL_TIM_COUNTERMODE_UP;
  TIM_InitStruct.Autoreload = 1600;
  TIM_InitStruct.ClockDivision = LL_TIM_CLOCKDIVISION_DIV1;
  LL_TIM_Init(TIM4, &TIM_InitStruct);
  LL_TIM_EnableARRPreload(TIM4);
  LL_TIM_SetClockSource(TIM4, LL_TIM_CLOCKSOURCE_INTERNAL);
  LL_TIM_OC_EnablePreload(TIM4, LL_TIM_CHANNEL_CH1);
  TIM_OC_InitStruct.OCMode = LL_TIM_OCMODE_PWM1;
  TIM_OC_InitStruct.OCState = LL_TIM_OCSTATE_DISABLE;
  TIM_OC_InitStruct.OCNState = LL_TIM_OCSTATE_DISABLE;
  TIM_OC_InitStruct.CompareValue = 0;
  TIM_OC_InitStruct.OCPolarity = LL_TIM_OCPOLARITY_HIGH;
  LL_TIM_OC_Init(TIM4, LL_TIM_CHANNEL_CH1, &TIM_OC_InitStruct);
  LL_TIM_OC_DisableFast(TIM4, LL_TIM_CHANNEL_CH1);
  LL_TIM_OC_EnablePreload(TIM4, LL_TIM_CHANNEL_CH2);
  LL_TIM_OC_Init(TIM4, LL_TIM_CHANNEL_CH2, &TIM_OC_InitStruct);
  LL_TIM_OC_DisableFast(TIM4, LL_TIM_CHANNEL_CH2);
  LL_TIM_OC_EnablePreload(TIM4, LL_TIM_CHANNEL_CH3);
  LL_TIM_OC_Init(TIM4, LL_TIM_CHANNEL_CH3, &TIM_OC_InitStruct);
  LL_TIM_OC_DisableFast(TIM4, LL_TIM_CHANNEL_CH3);
  LL_TIM_OC_EnablePreload(TIM4, LL_TIM_CHANNEL_CH4);
  LL_TIM_OC_Init(TIM4, LL_TIM_CHANNEL_CH4, &TIM_OC_InitStruct);
  LL_TIM_OC_DisableFast(TIM4, LL_TIM_CHANNEL_CH4);
  LL_TIM_SetOCRefClearInputSource(TIM4, LL_TIM_OCREF_CLR_INT_NC);
  LL_TIM_DisableExternalClock(TIM4);
  LL_TIM_ConfigETR(TIM4, LL_TIM_ETR_POLARITY_NONINVERTED, LL_TIM_ETR_PRESCALER_DIV1, LL_TIM_ETR_FILTER_FDIV1);
  LL_TIM_SetTriggerOutput(TIM4, LL_TIM_TRGO_RESET);
  LL_TIM_DisableMasterSlaveMode(TIM4);
  /* USER CODE BEGIN TIM4_Init 2 */
  LL_TIM_EnableCounter(TIM4);
  /* USER CODE END TIM4_Init 2 */
  LL_AHB2_GRP1_EnableClock(LL_AHB2_GRP1_PERIPH_GPIOD);
  /**TIM4 GPIO Configuration
  PD12   ------> TIM4_CH1
  PD13   ------> TIM4_CH2
  PD14   ------> TIM4_CH3
  PD15   ------> TIM4_CH4
  */
  GPIO_InitStruct.Pin = LL_GPIO_PIN_12|LL_GPIO_PIN_13|LL_GPIO_PIN_14|LL_GPIO_PIN_15;
  GPIO_InitStruct.Mode = LL_GPIO_MODE_ALTERNATE;
  GPIO_InitStruct.Speed = LL_GPIO_SPEED_FREQ_VERY_HIGH;
  GPIO_InitStruct.OutputType = LL_GPIO_OUTPUT_PUSHPULL;
  GPIO_InitStruct.Pull = LL_GPIO_PULL_NO;
  GPIO_InitStruct.Alternate = LL_GPIO_AF_2;
  LL_GPIO_Init(GPIOD, &GPIO_InitStruct);

}

static void MX_TIM5_Init(void)
{

  LL_TIM_InitTypeDef TIM_InitStruct = {0};
  LL_TIM_OC_InitTypeDef TIM_OC_InitStruct = {0};

  LL_GPIO_InitTypeDef GPIO_InitStruct = {0};

  /* Peripheral clock enable */
  LL_APB1_GRP1_EnableClock(LL_APB1_GRP1_PERIPH_TIM5);

  TIM_InitStruct.Prescaler = 0;
  TIM_InitStruct.CounterMode = LL_TIM_COUNTERMODE_UP;
  TIM_InitStruct.Autoreload = 1600;
  TIM_InitStruct.ClockDivision = LL_TIM_CLOCKDIVISION_DIV1;
  LL_TIM_Init(TIM5, &TIM_InitStruct);
  LL_TIM_EnableARRPreload(TIM5);
  LL_TIM_SetClockSource(TIM5, LL_TIM_CLOCKSOURCE_INTERNAL);
  LL_TIM_OC_EnablePreload(TIM5, LL_TIM_CHANNEL_CH1);
  TIM_OC_InitStruct.OCMode = LL_TIM_OCMODE_PWM1;
  TIM_OC_InitStruct.OCState = LL_TIM_OCSTATE_DISABLE;
  TIM_OC_InitStruct.OCNState = LL_TIM_OCSTATE_DISABLE;
  TIM_OC_InitStruct.CompareValue = 0;
  TIM_OC_InitStruct.OCPolarity = LL_TIM_OCPOLARITY_HIGH;
  LL_TIM_OC_Init(TIM5, LL_TIM_CHANNEL_CH1, &TIM_OC_InitStruct);
  LL_TIM_OC_DisableFast(TIM5, LL_TIM_CHANNEL_CH1);
  LL_TIM_OC_EnablePreload(TIM5, LL_TIM_CHANNEL_CH2);
  LL_TIM_OC_Init(TIM5, LL_TIM_CHANNEL_CH2, &TIM_OC_InitStruct);
  LL_TIM_OC_DisableFast(TIM5, LL_TIM_CHANNEL_CH2);
  LL_TIM_SetOCRefClearInputSource(TIM5, LL_TIM_OCREF_CLR_INT_NC);
  LL_TIM_DisableExternalClock(TIM5);
  LL_TIM_ConfigETR(TIM5, LL_TIM_ETR_POLARITY_NONINVERTED, LL_TIM_ETR_PRESCALER_DIV1, LL_TIM_ETR_FILTER_FDIV1);
  LL_TIM_SetTriggerOutput(TIM5, LL_TIM_TRGO_RESET);
  LL_TIM_DisableMasterSlaveMode(TIM5);
  /* USER CODE BEGIN TIM5_Init 2 */
  LL_TIM_EnableCounter(TIM5);
  /* USER CODE END TIM5_Init 2 */
  LL_AHB2_GRP1_EnableClock(LL_AHB2_GRP1_PERIPH_GPIOF);
  /**TIM5 GPIO Configuration
  PF6   ------> TIM5_CH1
  PF7   ------> TIM5_CH2
  */
  GPIO_InitStruct.Pin = LL_GPIO_PIN_6|LL_GPIO_PIN_7;
  GPIO_InitStruct.Mode = LL_GPIO_MODE_ALTERNATE;
  GPIO_InitStruct.Speed = LL_GPIO_SPEED_FREQ_VERY_HIGH;
  GPIO_InitStruct.OutputType = LL_GPIO_OUTPUT_PUSHPULL;
  GPIO_InitStruct.Pull = LL_GPIO_PULL_NO;
  GPIO_InitStruct.Alternate = LL_GPIO_AF_2;
  LL_GPIO_Init(GPIOF, &GPIO_InitStruct);

}

static void MX_TIM8_Init(void)
{

  LL_TIM_InitTypeDef TIM_InitStruct = {0};
  LL_TIM_OC_InitTypeDef TIM_OC_InitStruct = {0};
  LL_TIM_BDTR_InitTypeDef TIM_BDTRInitStruct = {0};

  LL_GPIO_InitTypeDef GPIO_InitStruct = {0};

  /* Peripheral clock enable */
  LL_APB2_GRP1_EnableClock(LL_APB2_GRP1_PERIPH_TIM8);

  TIM_InitStruct.Prescaler = 0;
  TIM_InitStruct.CounterMode = LL_TIM_COUNTERMODE_UP;
  TIM_InitStruct.Autoreload = 1600;
  TIM_InitStruct.ClockDivision = LL_TIM_CLOCKDIVISION_DIV1;
  TIM_InitStruct.RepetitionCounter = 0;
  LL_TIM_Init(TIM8, &TIM_InitStruct);
  LL_TIM_EnableARRPreload(TIM8);
  LL_TIM_SetClockSource(TIM8, LL_TIM_CLOCKSOURCE_INTERNAL);
  LL_TIM_OC_EnablePreload(TIM8, LL_TIM_CHANNEL_CH1);
  TIM_OC_InitStruct.OCMode = LL_TIM_OCMODE_PWM1;
  TIM_OC_InitStruct.OCState = LL_TIM_OCSTATE_DISABLE;
  TIM_OC_InitStruct.OCNState = LL_TIM_OCSTATE_DISABLE;
  TIM_OC_InitStruct.CompareValue = 0;
  TIM_OC_InitStruct.OCPolarity = LL_TIM_OCPOLARITY_HIGH;
  TIM_OC_InitStruct.OCNPolarity = LL_TIM_OCPOLARITY_HIGH;
  TIM_OC_InitStruct.OCIdleState = LL_TIM_OCIDLESTATE_LOW;
  TIM_OC_InitStruct.OCNIdleState = LL_TIM_OCIDLESTATE_LOW;
  LL_TIM_OC_Init(TIM8, LL_TIM_CHANNEL_CH1, &TIM_OC_InitStruct);
  LL_TIM_OC_DisableFast(TIM8, LL_TIM_CHANNEL_CH1);
  LL_TIM_OC_EnablePreload(TIM8, LL_TIM_CHANNEL_CH2);
  LL_TIM_OC_Init(TIM8, LL_TIM_CHANNEL_CH2, &TIM_OC_InitStruct);
  LL_TIM_OC_DisableFast(TIM8, LL_TIM_CHANNEL_CH2);
  LL_TIM_SetOCRefClearInputSource(TIM8, LL_TIM_OCREF_CLR_INT_NC);
  LL_TIM_DisableExternalClock(TIM8);
  LL_TIM_ConfigETR(TIM8, LL_TIM_ETR_POLARITY_NONINVERTED, LL_TIM_ETR_PRESCALER_DIV1, LL_TIM_ETR_FILTER_FDIV1);
  LL_TIM_SetTriggerOutput(TIM8, LL_TIM_TRGO_RESET);
  LL_TIM_SetTriggerOutput2(TIM8, LL_TIM_TRGO2_RESET);
  LL_TIM_DisableMasterSlaveMode(TIM8);
  TIM_BDTRInitStruct.OSSRState = LL_TIM_OSSR_DISABLE;
  TIM_BDTRInitStruct.OSSIState = LL_TIM_OSSI_DISABLE;
  TIM_BDTRInitStruct.LockLevel = LL_TIM_LOCKLEVEL_OFF;
  TIM_BDTRInitStruct.DeadTime = 0;
  TIM_BDTRInitStruct.BreakState = LL_TIM_BREAK_DISABLE;
  TIM_BDTRInitStruct.BreakPolarity = LL_TIM_BREAK_POLARITY_HIGH;
  TIM_BDTRInitStruct.BreakFilter = LL_TIM_BREAK_FILTER_FDIV1;
  TIM_BDTRInitStruct.Break2State = LL_TIM_BREAK2_DISABLE;
  TIM_BDTRInitStruct.Break2Polarity = LL_TIM_BREAK2_POLARITY_HIGH;
  TIM_BDTRInitStruct.Break2Filter = LL_TIM_BREAK2_FILTER_FDIV1;
  TIM_BDTRInitStruct.AutomaticOutput = LL_TIM_AUTOMATICOUTPUT_ENABLE;
  LL_TIM_BDTR_Init(TIM8, &TIM_BDTRInitStruct);
  /* USER CODE BEGIN TIM8_Init 2 */
  LL_TIM_EnableCounter(TIM8);
  /* USER CODE END TIM8_Init 2 */
  LL_AHB2_GRP1_EnableClock(LL_AHB2_GRP1_PERIPH_GPIOC);
  /**TIM8 GPIO Configuration
  PC6   ------> TIM8_CH1
  PC7   ------> TIM8_CH2
  */
  GPIO_InitStruct.Pin = LL_GPIO_PIN_6|LL_GPIO_PIN_7;
  GPIO_InitStruct.Mode = LL_GPIO_MODE_ALTERNATE;
  GPIO_InitStruct.Speed = LL_GPIO_SPEED_FREQ_LOW;
  GPIO_InitStruct.OutputType = LL_GPIO_OUTPUT_PUSHPULL;
  GPIO_InitStruct.Pull = LL_GPIO_PULL_NO;
  GPIO_InitStruct.Alternate = LL_GPIO_AF_3;
  LL_GPIO_Init(GPIOC, &GPIO_InitStruct);

}

static void MX_DMA_Init(void)
{

  /* DMA controller clock enable */
  __HAL_RCC_DMA1_CLK_ENABLE();

  /* DMA interrupt init */
  /* DMA1_Channel1_IRQn interrupt configuration */
  HAL_NVIC_SetPriority(DMA1_Channel1_IRQn, 0, 0);
  HAL_NVIC_EnableIRQ(DMA1_Channel1_IRQn);

}

static void MX_GPIO_Init(void)
{
  GPIO_InitTypeDef GPIO_InitStruct = {0};

  /* GPIO Ports Clock Enable */
  __HAL_RCC_GPIOE_CLK_ENABLE();
  __HAL_RCC_GPIOC_CLK_ENABLE();
  __HAL_RCC_GPIOF_CLK_ENABLE();
  __HAL_RCC_GPIOH_CLK_ENABLE();
  __HAL_RCC_GPIOA_CLK_ENABLE();
  __HAL_RCC_GPIOB_CLK_ENABLE();
  __HAL_RCC_GPIOG_CLK_ENABLE();
  __HAL_RCC_GPIOD_CLK_ENABLE();
  HAL_PWREx_EnableVddIO2();

  /*Configure GPIO pin Output Level */
  HAL_GPIO_WritePin(GPIOE, DO_PWR_EN_VALVE_Pin|DO_PWR_EN_PUMP3_Pin|DO_PUMP_DIR1_Pin|DO_PUMP_DIR2_Pin
                          |DO_PUMP_DIR3_Pin|DO_DBG_LED_HB_Pin, GPIO_PIN_RESET);

  /*Configure GPIO pin Output Level */
  HAL_GPIO_WritePin(GPIOC, DO_PWR_EN_MMI_Pin|DO_SENSOR1_SEL_Pin|DO_SENSOR2_SEL_Pin|DO_SENSOR3_SEL_Pin, GPIO_PIN_RESET);

  /*Configure GPIO pin Output Level */
  HAL_GPIO_WritePin(GPIOF, DO_PWR_EN_MODEM_Pin|DO_PWR_EN_5V_Pin|DO_MEASURE_EN_Pin, GPIO_PIN_SET);

  /*Configure GPIO pin Output Level */
  HAL_GPIO_WritePin(GPIOB, DO_PWR_EN_POS_Pin|DO_PWR_EN_5VSENS_Pin, GPIO_PIN_SET);

  /*Configure GPIO pin Output Level */
  HAL_GPIO_WritePin(GPIOG, DO_PWR_EN_PUMP1_Pin|DO_PWR_EN_PUMP2_Pin|DO_PWR_EN_FU_Pin, GPIO_PIN_RESET);

  /*Configure GPIO pin Output Level */
  HAL_GPIO_WritePin(DO_PWR_EN_24VSENS_GPIO_Port, DO_PWR_EN_24VSENS_Pin, GPIO_PIN_SET);

  /*Configure GPIO pin Output Level */
  HAL_GPIO_WritePin(GPIOB, DO_SENSOR16_SEL_Pin|DO_SENSOR17_SEL_Pin|DO_LED_EXTRA1_Pin|DO_A_MUX_SEL_Pin, GPIO_PIN_RESET);

  /*Configure GPIO pin Output Level */
  HAL_GPIO_WritePin(GPIOD, DO_SENSOR18_SEL_Pin|DO_PWR_EN_MEM_Pin|DO_SENSOR4_SEL_Pin|DO_SENSOR5_SEL_Pin
                          |DO_SENSOR6_SEL_Pin|DO_SENSOR7_SEL_Pin, GPIO_PIN_RESET);

  /*Configure GPIO pin Output Level */
  HAL_GPIO_WritePin(DO_MEM_RST_GPIO_Port, DO_MEM_RST_Pin, GPIO_PIN_SET);

  /*Configure GPIO pin Output Level */
  HAL_GPIO_WritePin(GPIOG, DO_nCS_FLASH_Pin|DO_nCS_FRAM_Pin, GPIO_PIN_SET);

  /*Configure GPIO pin Output Level */
  HAL_GPIO_WritePin(GPIOA, DO_MDM_PWR_KEY_Pin|DO_PWR_EN_UV_Pin, GPIO_PIN_RESET);

  /*Configure GPIO pins : DO_PWR_EN_VALVE_Pin DO_PWR_EN_PUMP3_Pin DO_PUMP_DIR1_Pin DO_PUMP_DIR2_Pin
                           DO_PUMP_DIR3_Pin DO_DBG_LED_HB_Pin DO_PWR_EN_24VSENS_Pin */
  GPIO_InitStruct.Pin = DO_PWR_EN_VALVE_Pin|DO_PWR_EN_PUMP3_Pin|DO_PUMP_DIR1_Pin|DO_PUMP_DIR2_Pin
                          |DO_PUMP_DIR3_Pin|DO_DBG_LED_HB_Pin|DO_PWR_EN_24VSENS_Pin;
  GPIO_InitStruct.Mode = GPIO_MODE_OUTPUT_PP;
  GPIO_InitStruct.Pull = GPIO_NOPULL;
  GPIO_InitStruct.Speed = GPIO_SPEED_FREQ_LOW;
  HAL_GPIO_Init(GPIOE, &GPIO_InitStruct);

  /*Configure GPIO pins : DO_PWR_EN_MMI_Pin DO_SENSOR1_SEL_Pin DO_SENSOR2_SEL_Pin DO_SENSOR3_SEL_Pin */
  GPIO_InitStruct.Pin = DO_PWR_EN_MMI_Pin|DO_SENSOR1_SEL_Pin|DO_SENSOR2_SEL_Pin|DO_SENSOR3_SEL_Pin;
  GPIO_InitStruct.Mode = GPIO_MODE_OUTPUT_PP;
  GPIO_InitStruct.Pull = GPIO_NOPULL;
  GPIO_InitStruct.Speed = GPIO_SPEED_FREQ_LOW;
  HAL_GPIO_Init(GPIOC, &GPIO_InitStruct);

  /*Configure GPIO pins : DI_TANK_SENSOR1_Pin DI_TANK_SENSOR2_Pin DI_TANK_SENSOR3_Pin DI_TANK_SENSOR4_Pin
                           DI_TANK_SENSOR5_Pin */
  GPIO_InitStruct.Pin = DI_TANK_SENSOR1_Pin|DI_TANK_SENSOR2_Pin|DI_TANK_SENSOR3_Pin|DI_TANK_SENSOR4_Pin
                          |DI_TANK_SENSOR5_Pin;
  GPIO_InitStruct.Mode = GPIO_MODE_INPUT;
  GPIO_InitStruct.Pull = GPIO_PULLUP;
  HAL_GPIO_Init(GPIOF, &GPIO_InitStruct);

  /*Configure GPIO pins : DI_HW_CFG1_Pin DI_HW_REV0_Pin DI_HW_REV1_Pin */
  GPIO_InitStruct.Pin = DI_HW_CFG1_Pin|DI_HW_REV0_Pin|DI_HW_REV1_Pin;
  GPIO_InitStruct.Mode = GPIO_MODE_INPUT;
  GPIO_InitStruct.Pull = GPIO_NOPULL;
  HAL_GPIO_Init(GPIOF, &GPIO_InitStruct);

  /*Configure GPIO pins : DO_PWR_EN_MODEM_Pin DO_PWR_EN_5V_Pin DO_MEASURE_EN_Pin */
  GPIO_InitStruct.Pin = DO_PWR_EN_MODEM_Pin|DO_PWR_EN_5V_Pin|DO_MEASURE_EN_Pin;
  GPIO_InitStruct.Mode = GPIO_MODE_OUTPUT_PP;
  GPIO_InitStruct.Pull = GPIO_NOPULL;
  GPIO_InitStruct.Speed = GPIO_SPEED_FREQ_LOW;
  HAL_GPIO_Init(GPIOF, &GPIO_InitStruct);

  /*Configure GPIO pin : DI_HW_CFG0_Pin */
  GPIO_InitStruct.Pin = DI_HW_CFG0_Pin;
  GPIO_InitStruct.Mode = GPIO_MODE_INPUT;
  GPIO_InitStruct.Pull = GPIO_NOPULL;
  HAL_GPIO_Init(DI_HW_CFG0_GPIO_Port, &GPIO_InitStruct);

  /*Configure GPIO pins : DO_PWR_EN_POS_Pin DO_SENSOR16_SEL_Pin DO_SENSOR17_SEL_Pin DO_PWR_EN_5VSENS_Pin
                           DO_LED_EXTRA1_Pin DO_A_MUX_SEL_Pin */
  GPIO_InitStruct.Pin = DO_PWR_EN_POS_Pin|DO_SENSOR16_SEL_Pin|DO_SENSOR17_SEL_Pin|DO_PWR_EN_5VSENS_Pin
                          |DO_LED_EXTRA1_Pin|DO_A_MUX_SEL_Pin;
  GPIO_InitStruct.Mode = GPIO_MODE_OUTPUT_PP;
  GPIO_InitStruct.Pull = GPIO_NOPULL;
  GPIO_InitStruct.Speed = GPIO_SPEED_FREQ_LOW;
  HAL_GPIO_Init(GPIOB, &GPIO_InitStruct);

  /*Configure GPIO pins : XI_PUMP_FAULT1_Pin XI_PUMP_FAULT2_Pin XI_PUMP_FAULT3_Pin */
  GPIO_InitStruct.Pin = XI_PUMP_FAULT1_Pin|XI_PUMP_FAULT2_Pin|XI_PUMP_FAULT3_Pin;
  GPIO_InitStruct.Mode = GPIO_MODE_IT_FALLING;
  GPIO_InitStruct.Pull = GPIO_PULLUP;
  HAL_GPIO_Init(GPIOF, &GPIO_InitStruct);

  /*Configure GPIO pins : DO_PWR_EN_PUMP1_Pin DO_PWR_EN_PUMP2_Pin DO_nCS_FLASH_Pin DO_nCS_FRAM_Pin
                           DO_PWR_EN_FU_Pin */
  GPIO_InitStruct.Pin = DO_PWR_EN_PUMP1_Pin|DO_PWR_EN_PUMP2_Pin|DO_nCS_FLASH_Pin|DO_nCS_FRAM_Pin
                          |DO_PWR_EN_FU_Pin;
  GPIO_InitStruct.Mode = GPIO_MODE_OUTPUT_PP;
  GPIO_InitStruct.Pull = GPIO_NOPULL;
  GPIO_InitStruct.Speed = GPIO_SPEED_FREQ_LOW;
  HAL_GPIO_Init(GPIOG, &GPIO_InitStruct);

  /*Configure GPIO pins : DI_SENSOR16D_Pin DI_SENSOR17D_Pin */
  GPIO_InitStruct.Pin = DI_SENSOR16D_Pin|DI_SENSOR17D_Pin;
  GPIO_InitStruct.Mode = GPIO_MODE_INPUT;
  GPIO_InitStruct.Pull = GPIO_PULLUP;
  HAL_GPIO_Init(GPIOB, &GPIO_InitStruct);

  /*Configure GPIO pins : DO_SENSOR18_SEL_Pin DO_PWR_EN_MEM_Pin DO_MEM_RST_Pin DO_SENSOR4_SEL_Pin
                           DO_SENSOR5_SEL_Pin DO_SENSOR6_SEL_Pin DO_SENSOR7_SEL_Pin */
  GPIO_InitStruct.Pin = DO_SENSOR18_SEL_Pin|DO_PWR_EN_MEM_Pin|DO_MEM_RST_Pin|DO_SENSOR4_SEL_Pin
                          |DO_SENSOR5_SEL_Pin|DO_SENSOR6_SEL_Pin|DO_SENSOR7_SEL_Pin;
  GPIO_InitStruct.Mode = GPIO_MODE_OUTPUT_PP;
  GPIO_InitStruct.Pull = GPIO_NOPULL;
  GPIO_InitStruct.Speed = GPIO_SPEED_FREQ_LOW;
  HAL_GPIO_Init(GPIOD, &GPIO_InitStruct);

  /*Configure GPIO pin : DI_SENSOR18D_Pin */
  GPIO_InitStruct.Pin = DI_SENSOR18D_Pin;
  GPIO_InitStruct.Mode = GPIO_MODE_INPUT;
  GPIO_InitStruct.Pull = GPIO_PULLUP;
  HAL_GPIO_Init(DI_SENSOR18D_GPIO_Port, &GPIO_InitStruct);

  /*Configure GPIO pin : XI_PWR_FAULT_CUR_Pin */
  GPIO_InitStruct.Pin = XI_PWR_FAULT_CUR_Pin;
  GPIO_InitStruct.Mode = GPIO_MODE_IT_FALLING;
  GPIO_InitStruct.Pull = GPIO_PULLUP;
  HAL_GPIO_Init(XI_PWR_FAULT_CUR_GPIO_Port, &GPIO_InitStruct);

  /*Configure GPIO pin : XI_MDM_STATUS_Pin */
  GPIO_InitStruct.Pin = XI_MDM_STATUS_Pin;
  GPIO_InitStruct.Mode = GPIO_MODE_IT_RISING_FALLING;
  GPIO_InitStruct.Pull = GPIO_PULLDOWN;
  HAL_GPIO_Init(XI_MDM_STATUS_GPIO_Port, &GPIO_InitStruct);

  /*Configure GPIO pins : DO_MDM_PWR_KEY_Pin DO_PWR_EN_UV_Pin */
  GPIO_InitStruct.Pin = DO_MDM_PWR_KEY_Pin|DO_PWR_EN_UV_Pin;
  GPIO_InitStruct.Mode = GPIO_MODE_OUTPUT_PP;
  GPIO_InitStruct.Pull = GPIO_NOPULL;
  GPIO_InitStruct.Speed = GPIO_SPEED_FREQ_LOW;
  HAL_GPIO_Init(GPIOA, &GPIO_InitStruct);

  /*Configure GPIO pin : DI_UV_ON_Pin */
  GPIO_InitStruct.Pin = DI_UV_ON_Pin;
  GPIO_InitStruct.Mode = GPIO_MODE_INPUT;
  GPIO_InitStruct.Pull = GPIO_PULLDOWN;
  HAL_GPIO_Init(DI_UV_ON_GPIO_Port, &GPIO_InitStruct);

  /*Configure GPIO pins : XI_PWR_FAULT_SENS_Pin XI_PWR_FAULT_FU_Pin */
  GPIO_InitStruct.Pin = XI_PWR_FAULT_SENS_Pin|XI_PWR_FAULT_FU_Pin;
  GPIO_InitStruct.Mode = GPIO_MODE_IT_FALLING;
  GPIO_InitStruct.Pull = GPIO_PULLUP;
  HAL_GPIO_Init(GPIOD, &GPIO_InitStruct);

  /*Configure GPIO pins : DIO_FU1_Pin DIO_FU2_Pin DIO_FU3_Pin DIO_FU4_Pin
                           DIO_FU5_Pin DIO_FU6_Pin */
  GPIO_InitStruct.Pin = DIO_FU1_Pin|DIO_FU2_Pin|DIO_FU3_Pin|DIO_FU4_Pin
                          |DIO_FU5_Pin|DIO_FU6_Pin;
  GPIO_InitStruct.Mode = GPIO_MODE_ANALOG;
  GPIO_InitStruct.Pull = GPIO_NOPULL;
  HAL_GPIO_Init(GPIOG, &GPIO_InitStruct);

  /*Configure GPIO pins : DI_BTN_2_NC_Pin DI_BTN_2_NO_Pin DI_BTN_1_NC_Pin */
  GPIO_InitStruct.Pin = DI_BTN_2_NC_Pin|DI_BTN_2_NO_Pin|DI_BTN_1_NC_Pin;
  GPIO_InitStruct.Mode = GPIO_MODE_INPUT;
  GPIO_InitStruct.Pull = GPIO_PULLDOWN;
  HAL_GPIO_Init(GPIOB, &GPIO_InitStruct);

  /*Configure GPIO pin : DI_BTN_1_NO_Pin */
  GPIO_InitStruct.Pin = DI_BTN_1_NO_Pin;
  GPIO_InitStruct.Mode = GPIO_MODE_INPUT;
  GPIO_InitStruct.Pull = GPIO_PULLDOWN;
  HAL_GPIO_Init(DI_BTN_1_NO_GPIO_Port, &GPIO_InitStruct);

  /*Configure GPIO pin : XI_PWR_FAULT_24V_Pin */
  GPIO_InitStruct.Pin = XI_PWR_FAULT_24V_Pin;
  GPIO_InitStruct.Mode = GPIO_MODE_IT_FALLING;
  GPIO_InitStruct.Pull = GPIO_PULLUP;
  HAL_GPIO_Init(XI_PWR_FAULT_24V_GPIO_Port, &GPIO_InitStruct);

  /* EXTI interrupt init*/
  HAL_NVIC_SetPriority(EXTI1_IRQn, 0, 0);
  HAL_NVIC_EnableIRQ(EXTI1_IRQn);

  HAL_NVIC_SetPriority(EXTI4_IRQn, 0, 0);
  HAL_NVIC_EnableIRQ(EXTI4_IRQn);

  HAL_NVIC_SetPriority(EXTI9_5_IRQn, 0, 0);
  HAL_NVIC_EnableIRQ(EXTI9_5_IRQn);

  HAL_NVIC_SetPriority(EXTI15_10_IRQn, 0, 0);
  HAL_NVIC_EnableIRQ(EXTI15_10_IRQn);

}

void HAL_TIM_PeriodElapsedCallback(TIM_HandleTypeDef *htim)
{
  if (htim->Instance == TIM16) {
    HAL_IncTick();
  }
}

void Error_Handler(void)
{
  __disable_irq();
  while (1)
  {
  }
}
